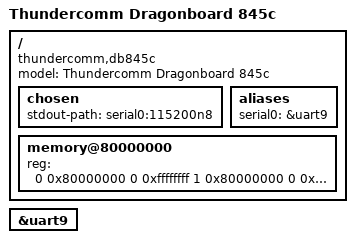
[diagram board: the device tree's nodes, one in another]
// SPDX-License-Identifier: GPL-2.0+
/*
 * Qualcomm Robotics RB3 Development (dragonboard845c) board device
 * tree source
 *
 * (C) Copyright 2022 Sumit Garg <sumit.garg@linaro.org>
 */

/dts-v1/;

#include "sdm845.dtsi"
#include "pm8998.dtsi"

/ {
	model = "Thundercomm Dragonboard 845c";
	compatible = "thundercomm,db845c", "qcom,sdm845";

	chosen {
		stdout-path = "serial0:115200n8";
	};

	aliases {
		serial0 = &uart9;
	};

	memory@80000000 {
		device_type = "memory";
		/* enchilada */
		reg = <0 0x80000000 0 0xffffffff
		       1 0x80000000 0 0xfc8a0000>;
		/* db845c */
		//reg = <0 0x80000000 0 0xfdfa0000>;
	};
};

&uart9 {
	status = "okay";
};
